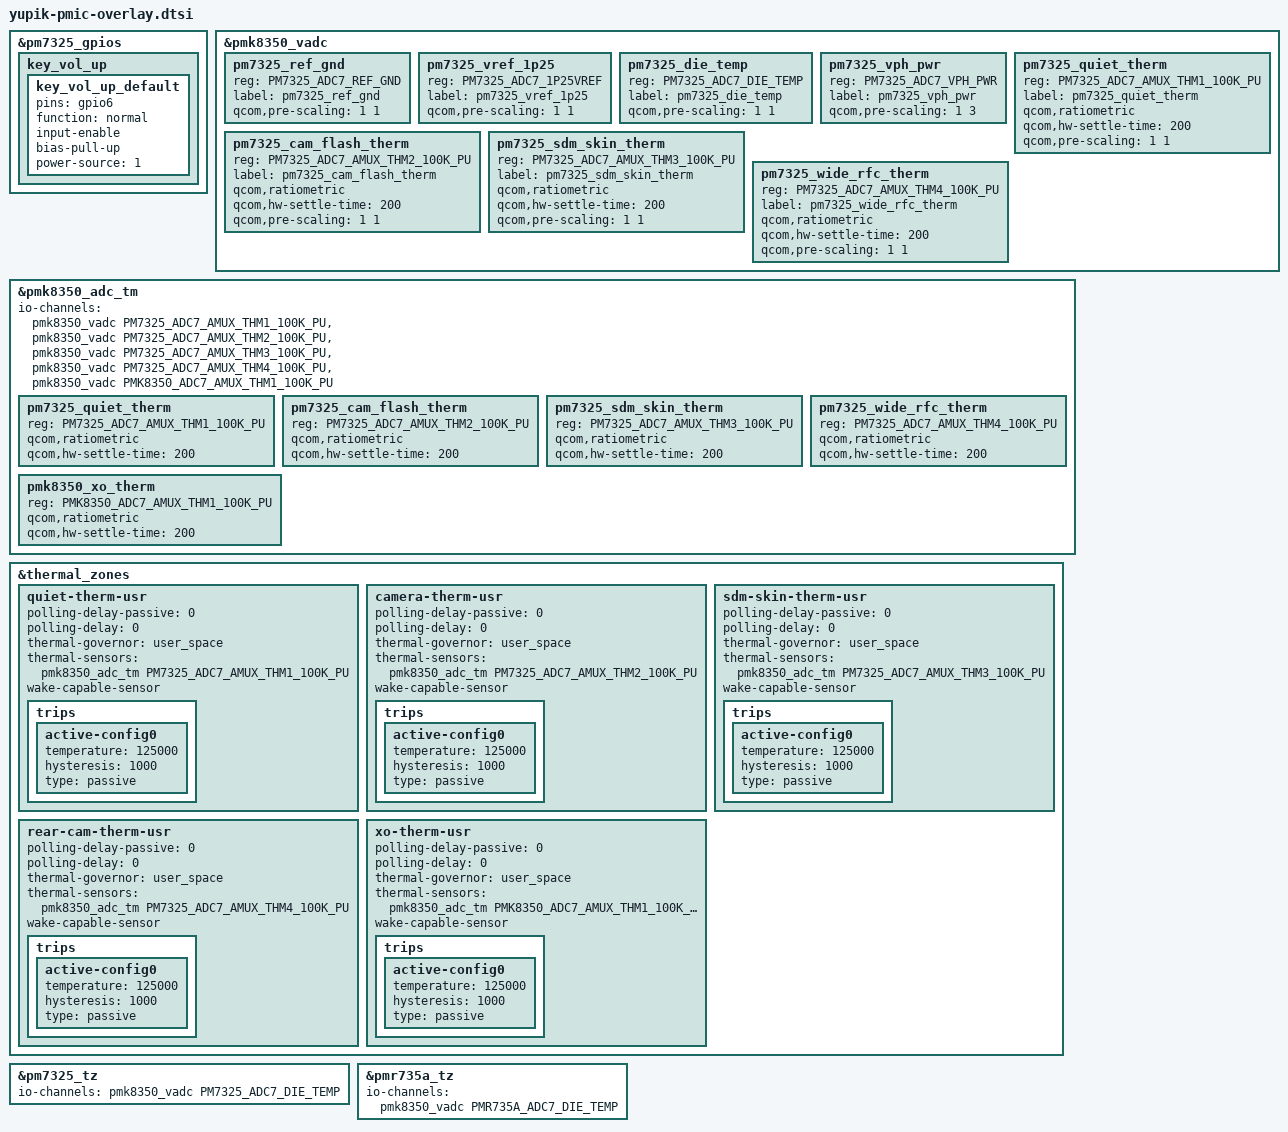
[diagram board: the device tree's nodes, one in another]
#include <dt-bindings/pinctrl/qcom,pmic-gpio.h>
#include <dt-bindings/iio/qcom,spmi-adc7-pm7325.h>

#include "pmk8350.dtsi"
#include "pm7325.dtsi"
#include "pm8350c.dtsi"
#include "pmr735a.dtsi"

&pm7325_gpios {
	key_vol_up {
		key_vol_up_default: key_vol_up_default {
			pins = "gpio6";
			function = "normal";
			input-enable;
			bias-pull-up;
			power-source = <1>;
		};
	};
};

&pmk8350_vadc {
	/delete-node/ pm8350_ref_gnd;
	/delete-node/ pm8350_vref_1p25;
	/delete-node/ pm8350_die_temp;
	/delete-node/ pm8350_vph_pwr;

	/delete-node/ pm8350b_ref_gnd;
	/delete-node/ pm8350b_vref_1p25;
	/delete-node/ pm8350b_die_temp;
	/delete-node/ pm8350b_vph_pwr;
	/delete-node/ pm8350b_vbat_sns;

	/delete-node/ pmr735b_ref_gnd;
	/delete-node/ pmr735b_vref_1p25;
	/delete-node/ pmr735b_die_temp;

	/* PM7325 Channel nodes */
	pm7325_ref_gnd {
		reg = <PM7325_ADC7_REF_GND>;
		label = "pm7325_ref_gnd";
		qcom,pre-scaling = <1 1>;
	};

	pm7325_vref_1p25 {
		reg = <PM7325_ADC7_1P25VREF>;
		label = "pm7325_vref_1p25";
		qcom,pre-scaling = <1 1>;
	};

	pm7325_die_temp {
		reg = <PM7325_ADC7_DIE_TEMP>;
		label = "pm7325_die_temp";
		qcom,pre-scaling = <1 1>;
	};

	pm7325_vph_pwr {
		reg = <PM7325_ADC7_VPH_PWR>;
		label = "pm7325_vph_pwr";
		qcom,pre-scaling = <1 3>;
	};

	pm7325_quiet_therm {
		reg = <PM7325_ADC7_AMUX_THM1_100K_PU>;
		label = "pm7325_quiet_therm";
		qcom,ratiometric;
		qcom,hw-settle-time = <200>;
		qcom,pre-scaling = <1 1>;
	};

	pm7325_cam_flash_therm {
		reg = <PM7325_ADC7_AMUX_THM2_100K_PU>;
		label = "pm7325_cam_flash_therm";
		qcom,ratiometric;
		qcom,hw-settle-time = <200>;
		qcom,pre-scaling = <1 1>;
	};

	pm7325_sdm_skin_therm {
		reg = <PM7325_ADC7_AMUX_THM3_100K_PU>;
		label = "pm7325_sdm_skin_therm";
		qcom,ratiometric;
		qcom,hw-settle-time = <200>;
		qcom,pre-scaling = <1 1>;
	};

	pm7325_wide_rfc_therm {
		reg = <PM7325_ADC7_AMUX_THM4_100K_PU>;
		label = "pm7325_wide_rfc_therm";
		qcom,ratiometric;
		qcom,hw-settle-time = <200>;
		qcom,pre-scaling = <1 1>;
	};
};

&pmk8350_adc_tm {
	io-channels = <&pmk8350_vadc PM7325_ADC7_AMUX_THM1_100K_PU>,
			<&pmk8350_vadc PM7325_ADC7_AMUX_THM2_100K_PU>,
			<&pmk8350_vadc PM7325_ADC7_AMUX_THM3_100K_PU>,
			<&pmk8350_vadc PM7325_ADC7_AMUX_THM4_100K_PU>,
			<&pmk8350_vadc PMK8350_ADC7_AMUX_THM1_100K_PU>;

	pm7325_quiet_therm {
		reg = <PM7325_ADC7_AMUX_THM1_100K_PU>;
		qcom,ratiometric;
		qcom,hw-settle-time = <200>;
	};

	pm7325_cam_flash_therm {
		reg = <PM7325_ADC7_AMUX_THM2_100K_PU>;
		qcom,ratiometric;
		qcom,hw-settle-time = <200>;
	};

	pm7325_sdm_skin_therm {
		reg = <PM7325_ADC7_AMUX_THM3_100K_PU>;
		qcom,ratiometric;
		qcom,hw-settle-time = <200>;
	};

	pm7325_wide_rfc_therm {
		reg = <PM7325_ADC7_AMUX_THM4_100K_PU>;
		qcom,ratiometric;
		qcom,hw-settle-time = <200>;
	};

	pmk8350_xo_therm {
		reg = <PMK8350_ADC7_AMUX_THM1_100K_PU>;
		qcom,ratiometric;
		qcom,hw-settle-time = <200>;
	};
};

&thermal_zones {
	quiet-therm-usr {
		polling-delay-passive = <0>;
		polling-delay = <0>;
		thermal-governor = "user_space";
		thermal-sensors = <&pmk8350_adc_tm PM7325_ADC7_AMUX_THM1_100K_PU>;
		wake-capable-sensor;
		trips {
			active-config0 {
				temperature = <125000>;
				hysteresis = <1000>;
				type = "passive";
			};
		};
	};

	camera-therm-usr {
		polling-delay-passive = <0>;
		polling-delay = <0>;
		thermal-governor = "user_space";
		thermal-sensors = <&pmk8350_adc_tm PM7325_ADC7_AMUX_THM2_100K_PU>;
		wake-capable-sensor;
		trips {
			active-config0 {
				temperature = <125000>;
				hysteresis = <1000>;
				type = "passive";
			};
		};
	};

	sdm-skin-therm-usr {
		polling-delay-passive = <0>;
		polling-delay = <0>;
		thermal-governor = "user_space";
		thermal-sensors = <&pmk8350_adc_tm PM7325_ADC7_AMUX_THM3_100K_PU>;
		wake-capable-sensor;
		trips {
			active-config0 {
				temperature = <125000>;
				hysteresis = <1000>;
				type = "passive";
			};
		};
	};

	rear-cam-therm-usr {
		polling-delay-passive = <0>;
		polling-delay = <0>;
		thermal-governor = "user_space";
		thermal-sensors = <&pmk8350_adc_tm PM7325_ADC7_AMUX_THM4_100K_PU>;
		wake-capable-sensor;
		trips {
			active-config0 {
				temperature = <125000>;
				hysteresis = <1000>;
				type = "passive";
			};
		};
	};

	xo-therm-usr {
		polling-delay-passive = <0>;
		polling-delay = <0>;
		thermal-governor = "user_space";
		thermal-sensors = <&pmk8350_adc_tm PMK8350_ADC7_AMUX_THM1_100K_PU>;
		wake-capable-sensor;
		trips {
			active-config0 {
				temperature = <125000>;
				hysteresis = <1000>;
				type = "passive";
			};
		};
	};
};

&pm7325_tz {
	io-channels = <&pmk8350_vadc PM7325_ADC7_DIE_TEMP>;
	io-channel-names = "thermal";
};

&pmr735a_tz {
	io-channels = <&pmk8350_vadc PMR735A_ADC7_DIE_TEMP>;
	io-channel-names = "thermal";
};
